# SIMCOP_CONTROL_L3Interconnect register map
Vendor: Texas Instruments
Peripheral module from a debugger description file (folder omap4430).
Registers are 32-bit, access not given, reset 0x0 unless marked. A register's access mark holds for its fields unless they carry their own. Offsets are as the file gives them; lines under a group give offsets from that group; [hi:lo] are bit positions; {n}, {i} and the like mark numbered series; 'fields as' and 'values as' point back to an identical list; <NAME> marks a mode.

## SIMCOP_CONTROL_L3Interconnect
0x00 SIMCOP_HL_REVISION ro reset not defined — MODULE REVISION This register contains the IP revision code in binary coded digital. For example, we have: 0x01 = revision 0.1 and 0x21 = revision 2.1
  [31:0] REV — Revision ID
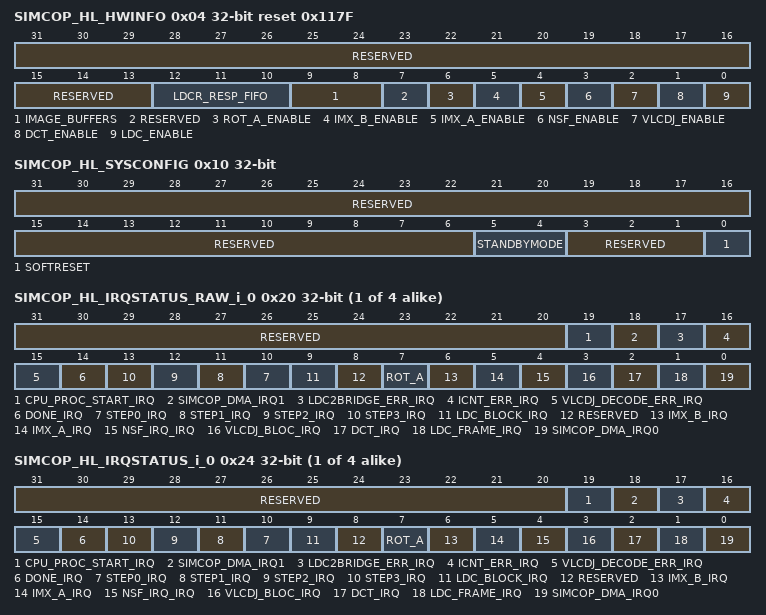
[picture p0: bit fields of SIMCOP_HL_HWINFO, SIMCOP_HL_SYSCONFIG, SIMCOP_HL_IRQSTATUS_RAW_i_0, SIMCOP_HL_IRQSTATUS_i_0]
0x04 SIMCOP_HL_HWINFO ro reset 0x117F — Information about the IP module's hardware configuration. It provides information about the generic parameters.
  [31:13] RESERVED — Read returns 0.
  [12:10] LDCR_RESP_FIFO — Defines the size of the LDC read master response FIFO in words of 128-bits.
    2=LDCR_RESP_FIFO_2_r (8x128 bits); 3=LDCR_RESP_FIFO_3_r (16x128 bits); 4=LDCR_RESP_FIFO_4_r (32x128 bits); 5=LDCR_RESP_FIFO_5_r (64x128 bits); 6=LDCR_RESP_FIFO_6_r (128x128 bits); 7=LDCR_RESP_FIFO_7_r (256x256 bits)
  [9:8] IMAGE_BUFFERS — This parameter defines the image buffer count.
    0=IMAGE_BUFFERS_0_r (4 Image buffers (e, f, g, h)); 1=IMAGE_BUFFERS_1_r (8 Image buffers)
  [7] RESERVED — Read returns 0.
  [6] ROT_A_ENABLE — The ROT a is present when this parameter is set.
    0=ROT_A_ENABLE_0_r (Disabled at design time); 1=ROT_A_ENABLE_1_r (Enabled at design time)
  [5] IMX_B_ENABLE — The iMX B module and the CMD b, COEFF b memories are present when this parameter is set.
    0=IMX_B_ENABLE_0_r (Disabled at design time); 1=IMX_B_ENABLE_1_r (Enabled at design time)
  [4] IMX_A_ENABLE — The iMX A module and the CMD a, COEFF a memories are present when this parameter is set.
    0=IMX_A_ENABLE_0_r (Disabled at design time); 1=IMX_A_ENABLE_1_r (Enabled at design time)
  [3] NSF_ENABLE — The NSF2 is present when this parameter is set.
    0=NSF_ENABLE_0_r (Disabled at design time); 1=NSF_ENABLE_1_r (Enabled at design time)
  [2] VLCDJ_ENABLE — The VLCD module and the QUANT, HUFFMAN, BITSTREAM memories are present when this parameter is set.
    0=VLCDJ_ENABLE_0_r (Disabled at design time); 1=VLCDJ_ENABLE_1_r (Enabled at design time)
  [1] DCT_ENABLE — The DCT module is present when this parameter is set.
    0=DCT_ENABLE_0_r (Disabled at design time); 1=DCT_ENABLE_1_r (Enabled at design time)
  [0] LDC_ENABLE — The LDC module and the LDC LUT are present when this parameter is set.
    0=LDC_ENABLE_0_r (Disabled at design time); 1=LDC_ENABLE_1_r (Enabled at design time)
0x10 SIMCOP_HL_SYSCONFIG access per field — This register controls the various parameters of the OCP interface
  [31:6] RESERVED ro — Read returns 0.
  [5:4] STANDBYMODE rw — Configuration of the local initiator state management mode. By definition, initiator may generate read/write transaction as long as it is out of STANDBY state.
    0=Force-standby mode: local initiator is unconditionally placed in standby state. Backup mode, for debug only.; 1=No-standby mode: local initiator is unconditionally placed out of standby state. Backup mode, for debug only.; 2=Smart-standby mode: local initiator standby status depends on local conditions, that is, the module's functional requirement from the initiator
  [3:1] RESERVED ro — Read returns 0.
  [0] SOFTRESET rw — Software reset
    0=SOFTRESET_0_r (Reset done, no pending action); 0=SOFTRESET_0_w (No action); 1=SOFTRESET_1_w (Initiate software reset); 1=SOFTRESET_1_r (Reset (software or other) ongoing)
{0x20+0x10*i} SIMCOP_HL_IRQSTATUS_RAW_i_{i} (i=0..3) — Per-event raw interrupt status vector Raw status is set even if event is not enabled. Write 1 to set the (raw) status, mostly for debug.
  [31:20] RESERVED ro — Read returns 0.
  [19] CPU_PROC_START_IRQ — Event triggered by the hardware sequencer to instruct the CPU to process a macroblock (access RW W1toSet)
    0=CPU_PROC_START_IRQ_0_w (No action); 0=CPU_PROC_START_IRQ_0_r (No event pending); 1=CPU_PROC_START_IRQ_1_r (Event pending); 1=CPU_PROC_START_IRQ_1_w (Set event (debug))
  [18] SIMCOP_DMA_IRQ1 ro — Event triggered by the SIMCOP DMA. This event is automatically cleared at SIMCOP level when it is cleared at SIMCOP DMA level. Check SIMCOP DMA IRQ registers.
    0=SIMCOP_DMA_IRQ1_0_r (No event pending); 1=SIMCOP_DMA_IRQ1_1_r (Event pending)
  [17] LDC2BRIDGE_ERR_IRQ — The LDC2 bridge has generated an error. (access RW W1toSet)
    0=LDC2BRIDGE_ERR_IRQ_0_w (No action); 0=LDC2BRIDGE_ERR_IRQ_0_r (No event pending); 1=LDC2BRIDGE_ERR_IRQ_1_r (Event pending); 1=LDC2BRIDGE_ERR_IRQ_1_w (Set event (debug))
  [16] ICNT_ERR_IRQ — An error has been received on the SIMCOP master port. (access RW W1toSet)
    0=ICNT_ERR_IRQ_0_w (No action); 0=ICNT_ERR_IRQ_0_r (No event pending); 1=ICNT_ERR_IRQ_1_r (Event pending); 1=ICNT_ERR_IRQ_1_w (Set event (debug))
  [15] VLCDJ_DECODE_ERR_IRQ — A decode error has been signaled by the VLCDJ module (access RW W1toSet)
    0=VLCDJ_DECODE_ERR_IRQ_0_w (No action); 0=VLCDJ_DECODE_ERR_IRQ_0_r (No event pending); 1=VLCDJ_DECODE_ERR_IRQ_1_r (Event pending); 1=VLCDJ_DECODE_ERR_IRQ_1_w (Set event (debug))
  [14] DONE_IRQ — Event triggered when the hardware sequencer finishes the sequence: - the sequence step counter has reached the limit - all accelerator and DMA events for the last sequence step have been received. (access RW W1toSet)
    0=DONE_IRQ_0_w (No action); 0=DONE_IRQ_0_r (No event pending); 1=DONE_IRQ_1_r (Event pending); 1=DONE_IRQ_1_w (Set event (debug))
  [n+10] STEP{n}_IRQ (n=0..3) — Event triggered when Step {n} is activated by the hardware sequencer (access RW W1toSet)
    0=STEP{n}_IRQ_0_w (No action); 0=STEP{n}_IRQ_0_r (No event pending); 1=STEP{n}_IRQ_1_r (Event pending); 1=STEP{n}_IRQ_1_w (Set event (debug))
  [9] LDC_BLOCK_IRQ — This event is triggered by LDC when a macroblock has been processed (access RW W1toSet)
    0=LDC_BLOCK_IRQ_0_w (No action); 0=LDC_BLOCK_IRQ_0_r (No event pending); 1=LDC_BLOCK_IRQ_1_r (Event pending); 1=LDC_BLOCK_IRQ_1_w (Set event (debug))
  [8] RESERVED ro — Read returns 0.
  [7] ROT_A — Event triggered by the ROT a engine (access RW W1toSet)
    0=ROT_A_0_w (No action); 0=ROT_A_0_r (No event pending); 1=ROT_A_1_r (Event pending); 1=ROT_A_1_w (Set event (debug))
  [6] IMX_B_IRQ — Event triggered when iMX has executed a SLEEP instruction. (access RW W1toSet)
    0=IMX_B_IRQ_0_w (No action); 0=IMX_B_IRQ_0_r (No event pending); 1=IMX_B_IRQ_1_r (Event pending); 1=IMX_B_IRQ_1_w (Set event (debug))
  [5] IMX_A_IRQ — Event triggered when iMX has executed a SLEEP instruction. (access RW W1toSet)
    0=IMX_A_IRQ_0_w (No action); 0=IMX_A_IRQ_0_r (No event pending); 1=IMX_A_IRQ_1_r (Event pending); 1=IMX_A_IRQ_1_w (Set event (debug))
  [4] NSF_IRQ_IRQ — Event triggered by the NSF2 imaging accelerator when processing of a block is done. (access RW W1toSet)
    0=NSF_IRQ_IRQ_0_w (No action); 0=NSF_IRQ_IRQ_0_r (No event pending); 1=NSF_IRQ_IRQ_1_r (Event pending); 1=NSF_IRQ_IRQ_1_w (Set event (debug))
  [3] VLCDJ_BLOC_IRQ — This event is triggered by VLCDJ when a macroblock has been processed (encode/decode) (access RW W1toSet)
    0=VLCDJ_BLOC_IRQ_0_w (No action); 0=VLCDJ_BLOC_IRQ_0_r (No event pending); 1=VLCDJ_BLOC_IRQ_1_r (Event pending); 1=VLCDJ_BLOC_IRQ_1_w (Set event (debug))
  [2] DCT_IRQ — Event triggered when a block has been processed by the DCT module and the filter outcome has been stored to an image buffer. (access RW W1toSet)
    0=DCT_IRQ_0_w (No action); 0=DCT_IRQ_0_r (No event pending); 1=DCT_IRQ_1_r (Event pending); 1=DCT_IRQ_1_w (Set event (debug))
  [1] LDC_FRAME_IRQ — This event is triggered by LDC when a full frame has been processed (access RW W1toSet)
    0=LDC_FRAME_IRQ_0_w (No action); 0=LDC_FRAME_IRQ_0_r (No event pending); 1=LDC_FRAME_IRQ_1_r (Event pending); 1=LDC_FRAME_IRQ_1_w (Set event (debug))
  [0] SIMCOP_DMA_IRQ0 ro — Event triggered by the SIMCOP DMA. This event is automatically cleared at SIMCOP level when it is cleared at SIMCOP DMA level. Check SIMCOP DMA IRQ registers.
    0=SIMCOP_DMA_IRQ0_0_r (No event pending); 1=SIMCOP_DMA_IRQ0_1_r (Event pending)
{0x24+0x10*i} SIMCOP_HL_IRQSTATUS_i_{i} (i=0..3) — Per-event 'enabled' interrupt status vector. Enabled status is not set unless event is enabled. Write 1 to clear the status after interrupt has been serviced (raw status gets cleared, that is, even if not enabled).
  [31:20] RESERVED ro — Read returns 0.
  [19] CPU_PROC_START_IRQ — Event triggered by the hardware sequencer to instruct the CPU to process a macroblock (access RW W1toClr)
    0=CPU_PROC_START_IRQ_0_w (No action); 0=CPU_PROC_START_IRQ_0_r (No (enabled) event pending); 1=CPU_PROC_START_IRQ_1_r (Event pending); 1=CPU_PROC_START_IRQ_1_w (Clear (raw) event)
  [18] SIMCOP_DMA_IRQ1 ro — Event triggered by the SIMCOP DMA. This event is automatically cleared at SIMCOP level when it is cleared at SIMCOP DMA level. Check SIMCOP DMA IRQ registers.
    0=SIMCOP_DMA_IRQ1_0_r (No (enabled) event pending); 1=SIMCOP_DMA_IRQ1_1_r (Event pending)
  [17] LDC2BRIDGE_ERR_IRQ — The LDC2 bridge has generated an error. (access RW W1toClr)
    0=LDC2BRIDGE_ERR_IRQ_0_w (No action); 0=LDC2BRIDGE_ERR_IRQ_0_r (No (enabled) event pending); 1=LDC2BRIDGE_ERR_IRQ_1_r (Event pending); 1=LDC2BRIDGE_ERR_IRQ_1_w (Clear (raw) event)
  [16] ICNT_ERR_IRQ — An error has been received on the SIMCOP master port. (access RW W1toClr)
    0=ICNT_ERR_IRQ_0_w (No action); 0=ICNT_ERR_IRQ_0_r (No (enabled) event pending); 1=ICNT_ERR_IRQ_1_r (Event pending); 1=ICNT_ERR_IRQ_1_w (Clear (raw) event)
  [15] VLCDJ_DECODE_ERR_IRQ — A decode error has been signaled by the VLCDJ module (access RW W1toClr)
    0=VLCDJ_DECODE_ERR_IRQ_0_w (No action); 0=VLCDJ_DECODE_ERR_IRQ_0_r (No (enabled) event pending); 1=VLCDJ_DECODE_ERR_IRQ_1_r (Event pending); 1=VLCDJ_DECODE_ERR_IRQ_1_w (Clear (raw) event)
  [14] DONE_IRQ — Event triggered when the hardware sequencer finishes the sequence: -The sequence step counter has reached the limit. All accelerator and DMA events for the last sequence step have been received. (access RW W1toClr)
    0=DONE_IRQ_0_w (No action); 0=DONE_IRQ_0_r (No (enabled) event pending); 1=DONE_IRQ_1_r (Event pending); 1=DONE_IRQ_1_w (Clear (raw) event)
  [n+10] STEP{n}_IRQ (n=0..3) — Event triggered when Step {n} is activated by the hardware sequencer (access RW W1toClr)
    0=STEP{n}_IRQ_0_w (No action); 0=STEP{n}_IRQ_0_r (No (enabled) event pending); 1=STEP{n}_IRQ_1_r (Event pending); 1=STEP{n}_IRQ_1_w (Clear (raw) event)
  [9] LDC_BLOCK_IRQ — This event is triggered by LDC when a macroblock has been processed (access RW W1toClr)
    0=LDC_BLOCK_IRQ_0_w (No action); 0=LDC_BLOCK_IRQ_0_r (No (enabled) event pending); 1=LDC_BLOCK_IRQ_1_r (Event pending); 1=LDC_BLOCK_IRQ_1_w (Clear (raw) event)
  [8] RESERVED ro — Read returns 0.
  [7] ROT_A — Event triggered by the ROT a engine (access RW W1toClr)
    0=ROT_A_0_w (No action); 0=ROT_A_0_r (No (enabled) event pending); 1=ROT_A_1_r (Event pending); 1=ROT_A_1_w (Clear (raw) event)
  [6] IMX_B_IRQ — Event triggered when iMX has executed a SLEEP instruction. (access RW W1toClr)
    0=IMX_B_IRQ_0_w (No action); 0=IMX_B_IRQ_0_r (No (enabled) event pending); 1=IMX_B_IRQ_1_r (Event pending); 1=IMX_B_IRQ_1_w (Clear (raw) event)
  [5] IMX_A_IRQ — Event triggered when iMX has executed a SLEEP instruction. (access RW W1toClr)
    0=IMX_A_IRQ_0_w (No action); 0=IMX_A_IRQ_0_r (No (enabled) event pending); 1=IMX_A_IRQ_1_r (Event pending); 1=IMX_A_IRQ_1_w (Clear (raw) event)
  [4] NSF_IRQ_IRQ — Event triggered by the NSF2 imaging accelerator when processing of a block is done. (access RW W1toClr)
    0=NSF_IRQ_IRQ_0_w (No action); 0=NSF_IRQ_IRQ_0_r (No (enabled) event pending); 1=NSF_IRQ_IRQ_1_r (Event pending); 1=NSF_IRQ_IRQ_1_w (Clear (raw) event)
  [3] VLCDJ_BLOC_IRQ — This event is triggered by VLCDJ when a macroblock has been processed (encode/decode) (access RW W1toClr)
    0=VLCDJ_BLOC_IRQ_0_w (No action); 0=VLCDJ_BLOC_IRQ_0_r (No (enabled) event pending); 1=VLCDJ_BLOC_IRQ_1_r (Event pending); 1=VLCDJ_BLOC_IRQ_1_w (Clear (raw) event)
  [2] DCT_IRQ — Event triggered when a block has been processed by the DCT module and the filter outcome has been stored to an image buffer. (access RW W1toClr)
    0=DCT_IRQ_0_w (No action); 0=DCT_IRQ_0_r (No (enabled) event pending); 1=DCT_IRQ_1_r (Event pending); 1=DCT_IRQ_1_w (Clear (raw) event)
  [1] LDC_FRAME_IRQ — This event is triggered by LDC when a full frame has been processed (access RW W1toClr)
    0=LDC_FRAME_IRQ_0_w (No action); 0=LDC_FRAME_IRQ_0_r (No (enabled) event pending); 1=LDC_FRAME_IRQ_1_r (Event pending); 1=LDC_FRAME_IRQ_1_w (Clear (raw) event)
  [0] SIMCOP_DMA_IRQ0 ro — Event triggered by the SIMCOP DMA. This event is automatically cleared at SIMCOP level when it is cleared at SIMCOP DMA level. Check SIMCOP DMA IRQ registers.
    0=SIMCOP_DMA_IRQ0_0_r (No (enabled) event pending); 1=SIMCOP_DMA_IRQ0_1_r (Event pending)
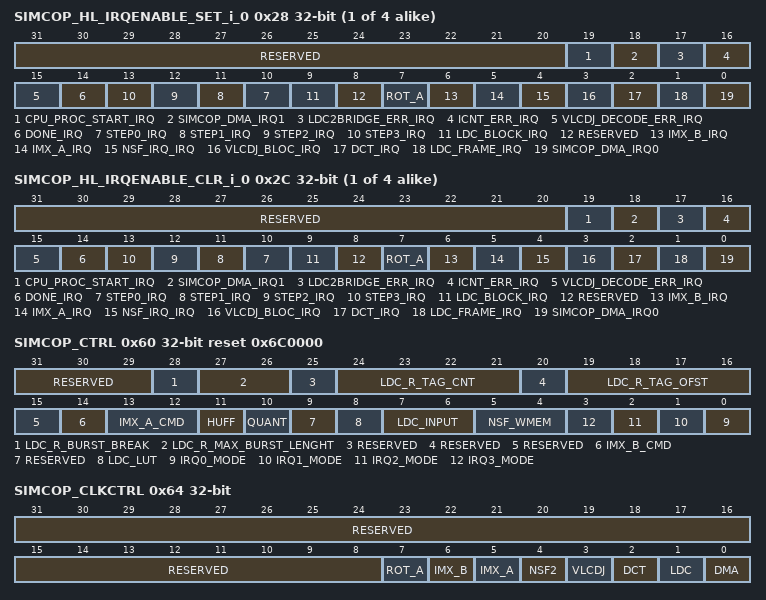
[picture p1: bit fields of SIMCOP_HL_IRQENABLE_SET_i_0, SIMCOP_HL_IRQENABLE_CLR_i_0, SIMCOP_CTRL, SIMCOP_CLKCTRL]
{0x28+0x10*i} SIMCOP_HL_IRQENABLE_SET_i_{i} (i=0..3) — Per-event interrupt enable bit vector. Write 1 to set (enable interrupt). Readout equal to corresponding _CLR register.
  [31:20] RESERVED ro — Read returns 0.
  [19] CPU_PROC_START_IRQ — Event triggered by the hardware sequencer to instruct the CPU to process a macroblock (access RW W1toSet)
    0=CPU_PROC_START_IRQ_0_w (No action); 0=CPU_PROC_START_IRQ_0_r (Interrupt disabled (masked)); 1=CPU_PROC_START_IRQ_1_r (Interrupt enabled); 1=CPU_PROC_START_IRQ_1_w (Enable interrupt)
  [18] SIMCOP_DMA_IRQ1 — Event triggered by the SIMCOP DMA. Check SIMCOP DMA IRQ registers. (access RW W1toSet)
    0=SIMCOP_DMA_IRQ1_0_w (No action); 0=SIMCOP_DMA_IRQ1_0_r (Interrupt disabled (masked)); 1=SIMCOP_DMA_IRQ1_1_r (Interrupt enabled); 1=SIMCOP_DMA_IRQ1_1_w (Enable interrupt)
  [17] LDC2BRIDGE_ERR_IRQ — The LDC2 bridge has generated an error. (access RW W1toSet)
    0=LDC2BRIDGE_ERR_IRQ_0_w (No action); 0=LDC2BRIDGE_ERR_IRQ_0_r (Interrupt disabled (masked)); 1=LDC2BRIDGE_ERR_IRQ_1_r (Interrupt enabled); 1=LDC2BRIDGE_ERR_IRQ_1_w (Enable interrupt)
  [16] ICNT_ERR_IRQ — An error has been received on the SIMCOP master port. (access RW W1toSet)
    0=ICNT_ERR_IRQ_0_w (No action); 0=ICNT_ERR_IRQ_0_r (Interrupt disabled (masked)); 1=ICNT_ERR_IRQ_1_r (Interrupt enabled); 1=ICNT_ERR_IRQ_1_w (Enable interrupt)
  [15] VLCDJ_DECODE_ERR_IRQ — A decode error has been signaled by the VLCDJ module (access RW W1toSet)
    0=VLCDJ_DECODE_ERR_IRQ_0_w (No action); 0=VLCDJ_DECODE_ERR_IRQ_0_r (Interrupt disabled (masked)); 1=VLCDJ_DECODE_ERR_IRQ_1_r (Interrupt enabled); 1=VLCDJ_DECODE_ERR_IRQ_1_w (Enable interrupt)
  [14] DONE_IRQ — Event triggered when the hardware sequencer finishes the sequence: The sequence step counter has reached the limit. All accelerator and DMA events for the last sequence step have been received. (access RW W1toSet)
    0=DONE_IRQ_0_w (No action); 0=DONE_IRQ_0_r (Interrupt disabled (masked)); 1=DONE_IRQ_1_r (Interrupt enabled); 1=DONE_IRQ_1_w (Enable interrupt)
  [n+10] STEP{n}_IRQ (n=0..3) — Event triggered when Step {n} is activated by the hardware sequencer (access RW W1toSet)
    0=STEP{n}_IRQ_0_w (No action); 0=STEP{n}_IRQ_0_r (Interrupt disabled (masked)); 1=STEP{n}_IRQ_1_r (Interrupt enabled); 1=STEP{n}_IRQ_1_w (Enable interrupt)
  [9] LDC_BLOCK_IRQ — This event is triggered by LDC when a macroblock has been processed (access RW W1toSet)
    0=LDC_BLOCK_IRQ_0_w (No action); 0=LDC_BLOCK_IRQ_0_r (Interrupt disabled (masked)); 1=LDC_BLOCK_IRQ_1_r (Interrupt enabled); 1=LDC_BLOCK_IRQ_1_w (Enable interrupt)
  [8] RESERVED ro — Read returns 0.
  [7] ROT_A — Event triggered by the ROT a engine (access RW W1toSet)
    0=ROT_A_0_w (No action); 0=ROT_A_0_r (Interrupt disabled (masked)); 1=ROT_A_1_r (Interrupt enabled); 1=ROT_A_1_w (Enable interrupt)
  [6] IMX_B_IRQ — Event triggered when iMX has executed a SLEEP instruction. (access RW W1toSet)
    0=IMX_B_IRQ_0_w (No action); 0=IMX_B_IRQ_0_r (Interrupt disabled (masked)); 1=IMX_B_IRQ_1_r (Interrupt enabled); 1=IMX_B_IRQ_1_w (Enable interrupt)
  [5] IMX_A_IRQ — Event triggered when iMX has executed a SLEEP instruction. (access RW W1toSet)
    0=IMX_A_IRQ_0_w (No action); 0=IMX_A_IRQ_0_r (Interrupt disabled (masked)); 1=IMX_A_IRQ_1_r (Interrupt enabled); 1=IMX_A_IRQ_1_w (Enable interrupt)
  [4] NSF_IRQ_IRQ — Event triggered by the NSF2 imaging accelerator when processing of a block is done. (access RW W1toSet)
    0=NSF_IRQ_IRQ_0_w (No action); 0=NSF_IRQ_IRQ_0_r (Interrupt disabled (masked)); 1=NSF_IRQ_IRQ_1_r (Interrupt enabled); 1=NSF_IRQ_IRQ_1_w (Enable interrupt)
  [3] VLCDJ_BLOC_IRQ — This event is triggered by VLCDJ when a macroblock has been processed (encode/decode) (access RW W1toSet)
    0=VLCDJ_BLOC_IRQ_0_w (No action); 0=VLCDJ_BLOC_IRQ_0_r (Interrupt disabled (masked)); 1=VLCDJ_BLOC_IRQ_1_r (Interrupt enabled); 1=VLCDJ_BLOC_IRQ_1_w (Enable interrupt)
  [2] DCT_IRQ — Event triggered when a block has been processed by the DCT module and the filter outcome has been stored to an image buffer. (access RW W1toSet)
    0=DCT_IRQ_0_w (No action); 0=DCT_IRQ_0_r (Interrupt disabled (masked)); 1=DCT_IRQ_1_r (Interrupt enabled); 1=DCT_IRQ_1_w (Enable interrupt)
  [1] LDC_FRAME_IRQ — This event is triggered by LDC when a full frame has been processed (access RW W1toSet)
    0=LDC_FRAME_IRQ_0_w (No action); 0=LDC_FRAME_IRQ_0_r (Interrupt disabled (masked)); 1=LDC_FRAME_IRQ_1_r (Interrupt enabled); 1=LDC_FRAME_IRQ_1_w (Enable interrupt)
  [0] SIMCOP_DMA_IRQ0 — Event triggered by the SIMCOP DMA. Check SIMCOP DMA IRQ registers. (access RW W1toSet)
    0=SIMCOP_DMA_IRQ0_0_w (No action); 0=SIMCOP_DMA_IRQ0_0_r (Interrupt disabled (masked)); 1=SIMCOP_DMA_IRQ0_1_r (Interrupt enabled); 1=SIMCOP_DMA_IRQ0_1_w (Enable interrupt)
{0x2C+0x10*i} SIMCOP_HL_IRQENABLE_CLR_i_{i} (i=0..3) — Per-event interrupt enable bit vector. Write 1 to clear (disable interrupt). Readout equal to corresponding _SET register.
  [31:20] RESERVED ro — Read returns 0.
  [19] CPU_PROC_START_IRQ — Event triggered by the hardware sequencer to instruct the CPU to process a macroblock (access RW W1toClr)
    0=CPU_PROC_START_IRQ_0_w (No action); 0=CPU_PROC_START_IRQ_0_r (Interrupt disabled (masked)); 1=CPU_PROC_START_IRQ_1_r (Interrupt enabled); 1=CPU_PROC_START_IRQ_1_w (Disable interrupt)
  [18] SIMCOP_DMA_IRQ1 — Event triggered by the SIMCOP DMA. Check SIMCOP DMA IRQ registers. (access RW W1toClr)
    0=SIMCOP_DMA_IRQ1_0_w (No action); 0=SIMCOP_DMA_IRQ1_0_r (Interrupt disabled (masked)); 1=SIMCOP_DMA_IRQ1_1_r (Interrupt enabled); 1=SIMCOP_DMA_IRQ1_1_w (Disable interrupt)
  [17] LDC2BRIDGE_ERR_IRQ — The LDC2 bridge has generated an error. (access RW W1toClr)
    0=LDC2BRIDGE_ERR_IRQ_0_w (No action); 0=LDC2BRIDGE_ERR_IRQ_0_r (Interrupt disabled (masked)); 1=LDC2BRIDGE_ERR_IRQ_1_r (Interrupt enabled); 1=LDC2BRIDGE_ERR_IRQ_1_w (Disable interrupt)
  [16] ICNT_ERR_IRQ — An error has been received on the SIMCOP master port. (access RW W1toClr)
    0=ICNT_ERR_IRQ_0_w (No action); 0=ICNT_ERR_IRQ_0_r (Interrupt disabled (masked)); 1=ICNT_ERR_IRQ_1_r (Interrupt enabled); 1=ICNT_ERR_IRQ_1_w (Disable interrupt)
  [15] VLCDJ_DECODE_ERR_IRQ — A decode error has been signaled by the VLCDJ module (access RW W1toClr)
    0=VLCDJ_DECODE_ERR_IRQ_0_w (No action); 0=VLCDJ_DECODE_ERR_IRQ_0_r (Interrupt disabled (masked)); 1=VLCDJ_DECODE_ERR_IRQ_1_r (Interrupt enabled); 1=VLCDJ_DECODE_ERR_IRQ_1_w (Disable interrupt)
  [14] DONE_IRQ — Event triggered when the hardware sequencer finishes the sequence: The sequence step counter has reached the limit. All accelerator and DMA events for the last sequence step have been received. (access RW W1toClr)
    0=DONE_IRQ_0_w (No action); 0=DONE_IRQ_0_r (Interrupt disabled (masked)); 1=DONE_IRQ_1_r (Interrupt enabled); 1=DONE_IRQ_1_w (Disable interrupt)
  [n+10] STEP{n}_IRQ (n=0..3) — Event triggered when Step {n} is activated by the hardware sequencer (access RW W1toClr)
    0=STEP{n}_IRQ_0_w (No action); 0=STEP{n}_IRQ_0_r (Interrupt disabled (masked)); 1=STEP{n}_IRQ_1_r (Interrupt enabled); 1=STEP{n}_IRQ_1_w (Disable interrupt)
  [9] LDC_BLOCK_IRQ — This event is triggered by LDC when a macroblock has been processed (access RW W1toClr)
    0=LDC_BLOCK_IRQ_0_w (No action); 0=LDC_BLOCK_IRQ_0_r (Interrupt disabled (masked)); 1=LDC_BLOCK_IRQ_1_r (Interrupt enabled); 1=LDC_BLOCK_IRQ_1_w (Disable interrupt)
  [8] RESERVED ro — Read returns 0.
  [7] ROT_A — Event triggered by the ROT a engine (access RW W1toClr)
    0=ROT_A_0_w (No action); 0=ROT_A_0_r (Interrupt disabled (masked)); 1=ROT_A_1_r (Interrupt enabled); 1=ROT_A_1_w (Disable interrupt)
  [6] IMX_B_IRQ — Event triggered when iMX has executed a SLEEP instruction. (access RW W1toClr)
    0=IMX_B_IRQ_0_w (No action); 0=IMX_B_IRQ_0_r (Interrupt disabled (masked)); 1=IMX_B_IRQ_1_r (Interrupt enabled); 1=IMX_B_IRQ_1_w (Disable interrupt)
  [5] IMX_A_IRQ — Event triggered when iMX has executed a SLEEP instruction. (access RW W1toClr)
    0=IMX_A_IRQ_0_w (No action); 0=IMX_A_IRQ_0_r (Interrupt disabled (masked)); 1=IMX_A_IRQ_1_r (Interrupt enabled); 1=IMX_A_IRQ_1_w (Disable interrupt)
  [4] NSF_IRQ_IRQ — Event triggered by the NSF2 imaging accelerator when processing of a block is done. (access RW W1toClr)
    0=NSF_IRQ_IRQ_0_w (No action); 0=NSF_IRQ_IRQ_0_r (Interrupt disabled (masked)); 1=NSF_IRQ_IRQ_1_r (Interrupt enabled); 1=NSF_IRQ_IRQ_1_w (Disable interrupt)
  [3] VLCDJ_BLOC_IRQ — This event is triggered by VLCDJ when a macroblock has been processed (encode/decode) (access RW W1toClr)
    0=VLCDJ_BLOC_IRQ_0_w (No action); 0=VLCDJ_BLOC_IRQ_0_r (Interrupt disabled (masked)); 1=VLCDJ_BLOC_IRQ_1_r (Interrupt enabled); 1=VLCDJ_BLOC_IRQ_1_w (Disable interrupt)
  [2] DCT_IRQ — Event triggered when a block has been processed by the DCT module and the filter outcome has been stored to an image buffer. (access RW W1toClr)
    0=DCT_IRQ_0_w (No action); 0=DCT_IRQ_0_r (Interrupt disabled (masked)); 1=DCT_IRQ_1_r (Interrupt enabled); 1=DCT_IRQ_1_w (Disable interrupt)
  [1] LDC_FRAME_IRQ — This event is triggered by LDC when a full frame has been processed (access RW W1toClr)
    0=LDC_FRAME_IRQ_0_w (No action); 0=LDC_FRAME_IRQ_0_r (Interrupt disabled (masked)); 1=LDC_FRAME_IRQ_1_r (Interrupt enabled); 1=LDC_FRAME_IRQ_1_w (Disable interrupt)
  [0] SIMCOP_DMA_IRQ0 — Event triggered by the SIMCOP DMA. Check SIMCOP DMA IRQ registers. (access RW W1toClr)
    0=SIMCOP_DMA_IRQ0_0_w (No action); 0=SIMCOP_DMA_IRQ0_0_r (Interrupt disabled (masked)); 1=SIMCOP_DMA_IRQ0_1_r (Interrupt enabled); 1=SIMCOP_DMA_IRQ0_1_w (Disable interrupt)
0x60 SIMCOP_CTRL access per field reset 0x6C0000 — SIMCOP control register
  [31:29] RESERVED ro — Read returns 0.
  [28] LDC_R_BURST_BREAK rw — Controls if bursts issued by the LDC2 bridge could cross burst length boundaries. When this register is set, the LDC2 bridge only issues aligned bursts. Register can only be used when LDC_R_MAX_BURST_LENGHT is 32, 64, or 128 bytes.
    0=Yes; 1=No. OCP transactions must be split
  [27:26] LDC_R_MAX_BURST_LENGHT rw — Limits the maximum burst length that could be used by the LDC2 bridge
    0=8 x 128; 1=6 x 128; 2=4 x 128; 3=2 x 128
  [25] RESERVED ro — Read returns 0.
  [24:21] LDC_R_TAG_CNT rw — Limits the maximum number of outstanding requests to LDC_R_TAG_CNT+1
  [20] RESERVED ro — Read returns 0.
  [19:16] LDC_R_TAG_OFST rw — First OCP tag ID that can be used by LDC reads.Software must prevent overlap with tags generated by the SIMCOP DMA.Typically this value should be equal to SIMCP_DMA_CTRL.TAG_CNT+1.
  [15] RESERVED ro — Read returns 0.
  [14] IMX_B_CMD rw — Switch for iMX # command memory
    0=Coprocessor bus; 1=iMX B instruction read / write
  [13:12] IMX_A_CMD rw — Switch for iMX A command memory
    0=Coprocessor bus; 1=iMX A instruction read/write; 2=iMX B instruction read/write
  [11] HUFF rw — Switch for Huffman table
    0=Coprocessor; 1=VLCDJ Huffman table read
  [10] QUANT rw — Switch for quantization table
    0=Coprocessor bus; 1=VLCDJ quantization table read
  [9] RESERVED ro — Read returns 0.
  [8] LDC_LUT rw — Switch for LDC LUT
    0=Coprocessor bus; 1=The LDC module could access the LDC LUT
  [7:6] LDC_INPUT rw — Selects input data buffer for LDC. Memories attached to LDC as working memories cannot be used by any other accelerators. HWSEQ or HWSEQ software override settings are ignored for those memories.
    0=No input memory attached; 1=Use image buffers a and b; 2=Use image buffers a, b, c, and d; 3=Use LDC private input memory
  [5:4] NSF_WMEM rw — Selects working memory for NSF. Memories attached to NSF as working memories cannot be used by any other accelerators. HWSEQ or HWSEQ software override settings are ignored for those memories.
    0=No working memory attached to NSF2. NSF2 cannot be used.; 1=iMX A coefficient memory used; 2=Image buffers a and b used. Those image buffers cannot be used for other purposes. This setting has higher priority than the context configuration.; 3=Image buffers a, b, c, and d used. Those image buffers cannot be used for other purposes. This setting has higher priority than the context configuration.
  [n] IRQ{n}_MODE rw (n=0..3) — Interrupt generation method
    0=The interrupt line is asserted when one of the events enabled in SIMCOP_IRQENABLE_{n} is pending; 1=The interrupt line is asserted when all events enabled in SIMCOP_IRQENABLE_{n} are pending
0x64 SIMCOP_CLKCTRL access per field — SIMCOP clock control register. Use to enable/disable the interface and functional clock of SIMCOP submodules. Disabled modules cannot be accessed
  [31:8] RESERVED ro — Read returns 0.
  [7] ROT_A rw
    0=ROT_A_0_w (Request shutdown of the submodule. No effect if the submodule clock is already off.); 0=ROT_A_0_r (The submodule is off); 1=ROT_A_1_r (The submodule is on); 1=ROT_A_1_w (Request enable of the submodule. No effect if the submodule clock is already off.)
  [6] IMX_B rw
    0=IMX_B_0_w (Request shutdown of the submodule. No effect if the submodule clock is already off.); 0=IMX_B_0_r (The submodule is off.); 1=IMX_B_1_r (The submodule is on.); 1=IMX_B_1_w (Request enable of the submodule. No effect if the submodule clock is already off.)
  [5] IMX_A rw
    0=IMX_A_0_w (Request shutdown of the submodule. No effect if the submodule clock is already off.); 0=IMX_A_0_r (The submodule is off.); 1=IMX_A_1_r (The submodule is on.); 1=IMX_A_1_w (Request enable of the submodule. No effect if the submodule clock is already off.)
  [4] NSF2 rw
    0=NSF2_0_w (Request shutdown of the submodule. No effect if the submodule clock is already off.); 0=NSF2_0_r (The submodule is off.); 1=NSF2_1_r (The submodule is on.); 1=NSF2_1_w (Request enable of the submodule. No effect if the submodule clock is already off.)
  [3] VLCDJ rw
    0=VLCDJ_0_w (Request shutdown of the submodule. No effect if the submodule clock is already off.); 0=VLCDJ_0_r (The submodule is off.); 1=VLCDJ_1_r (The submodule is on.); 1=VLCDJ_1_w (Request enable of the submodule. No effect if the submodule clock is already off.)
  [2] DCT rw
    0=DCT_0_w (Request shutdown of the submodule. No effect if the submodule clock is already off.); 0=DCT_0_r (The submodule is off.); 1=DCT_1_r (The submodule is on.); 1=DCT_1_w (Request enable of the submodule. No effect if the submodule clock is already off.)
  [1] LDC rw
    0=LDC_0_w (Request shutdown of the submodule. No effect if the submodule clock is already off.); 0=LDC_0_r (The submodule is off.); 1=LDC_1_r (The submodule is on.); 1=LDC_1_w (Request enable of the submodule. No effect if the submodule clock is already off.)
  [0] DMA rw
    0=DMA_0_w (Request shutdown of the submodule. No effect if the submodule clock is already off.); 0=DMA_0_r (The submodule is off.); 1=DMA_1_r (The submodule is on.); 1=DMA_1_w (Request enable of the submodule. No effect if the submodule clock is already off.)
